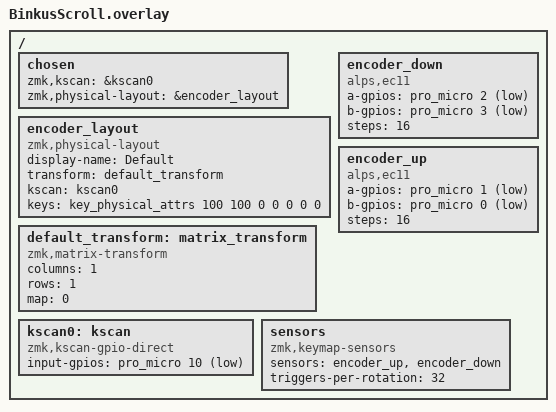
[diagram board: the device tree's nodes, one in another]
#include <physical_layouts.dtsi>

/ {
    chosen {
        zmk,kscan = &kscan0;
        zmk,physical-layout = &encoder_layout;
    };

    // Physical layout for ZMK Studio
    encoder_layout: encoder_layout {
        compatible = "zmk,physical-layout";
        display-name = "Default";
        transform = <&default_transform>;
        kscan = <&kscan0>;
        
        keys  // w h x y rot rx ry
            = <&key_physical_attrs 100 100 0 0 0 0 0>
            ;
    };

    // Matrix transform - single position
    default_transform: matrix_transform {
        compatible = "zmk,matrix-transform";
        columns = <1>;
        rows = <1>;
        map = <0>;
    };

    // Minimal dummy kscan (ZMK requires this even with just encoder)
    kscan0: kscan {
        compatible = "zmk,kscan-gpio-direct";
        input-gpios = <&pro_micro 10 (GPIO_ACTIVE_LOW | GPIO_PULL_UP)>;
    };

    // Encoder 1 - Scroll Down
    encoder_down: encoder_down {
        compatible = "alps,ec11";
        a-gpios = <&pro_micro 2 (GPIO_ACTIVE_LOW | GPIO_PULL_UP)>;
        b-gpios = <&pro_micro 3 (GPIO_ACTIVE_LOW | GPIO_PULL_UP)>;
        steps = <16>;
        status = "okay";
    };

    // Encoder 2 - Scroll Up
    encoder_up: encoder_up {
        compatible = "alps,ec11";
        a-gpios = <&pro_micro 1 (GPIO_ACTIVE_LOW | GPIO_PULL_UP)>;  // Replace XX with your GPIO
        b-gpios = <&pro_micro 0 (GPIO_ACTIVE_LOW | GPIO_PULL_UP)>;  // Replace YY with your GPIO
        steps = <16>;
        status = "okay";
    };

    sensors: sensors {
        compatible = "zmk,keymap-sensors";
        sensors = <&encoder_up &encoder_down>;
        triggers-per-rotation = <32>;
    };
};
